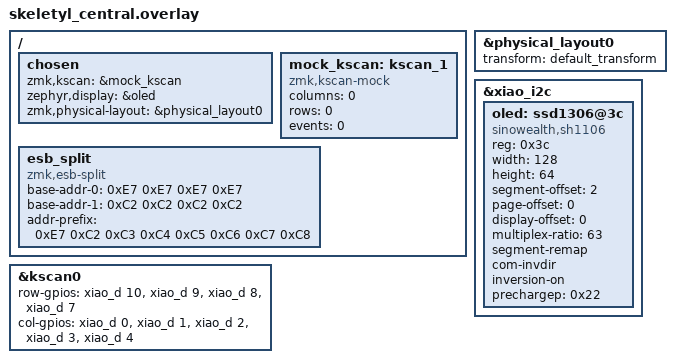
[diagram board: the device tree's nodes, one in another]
#include "skeletyl.dtsi"

&physical_layout0 {
    transform = <&default_transform>;
};

&kscan0 {
    row-gpios
        = <&xiao_d 10 (GPIO_ACTIVE_HIGH | GPIO_PULL_DOWN)>
        , <&xiao_d 9 (GPIO_ACTIVE_HIGH | GPIO_PULL_DOWN)>
        , <&xiao_d 8 (GPIO_ACTIVE_HIGH | GPIO_PULL_DOWN)>
        , <&xiao_d 7 (GPIO_ACTIVE_HIGH | GPIO_PULL_DOWN)>
        ;
    col-gpios
        = <&xiao_d 0 GPIO_ACTIVE_HIGH>
        , <&xiao_d 1 GPIO_ACTIVE_HIGH>
        , <&xiao_d 2 GPIO_ACTIVE_HIGH>
        , <&xiao_d 3 GPIO_ACTIVE_HIGH>
        , <&xiao_d 4 GPIO_ACTIVE_HIGH>
        ;
};

/ {
    chosen {
        zmk,kscan = &mock_kscan;
        zephyr,display = &oled;
        zmk,physical-layout = &physical_layout0;
    };

    mock_kscan: kscan_1 {
        compatible = "zmk,kscan-mock";
        columns = <0>;
        rows = <0>;
        events = <0>;
    };
    esb_split {
        compatible = "zmk,esb-split";
        // These are arbitrary default addresses. In end user products
        // different addresses should be used for each set of devices.
        base-addr-0 = <0xE7 0xE7 0xE7 0xE7>;
        base-addr-1 = <0xC2 0xC2 0xC2 0xC2>;
        addr-prefix = <0xE7 0xC2 0xC3 0xC4 0xC5 0xC6 0xC7 0xC8>;
    };
};

&xiao_i2c {
    status = "okay";
    
    oled: ssd1306@3c {
        compatible = "sinowealth,sh1106";
        reg = <0x3c>;
        width = <128>;
        height = <64>;
        segment-offset = <2>;
        page-offset = <0>;
        display-offset = <0>;
        multiplex-ratio = <63>;
        segment-remap;
        com-invdir;
        inversion-on;
        prechargep = <0x22>;
    };
};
